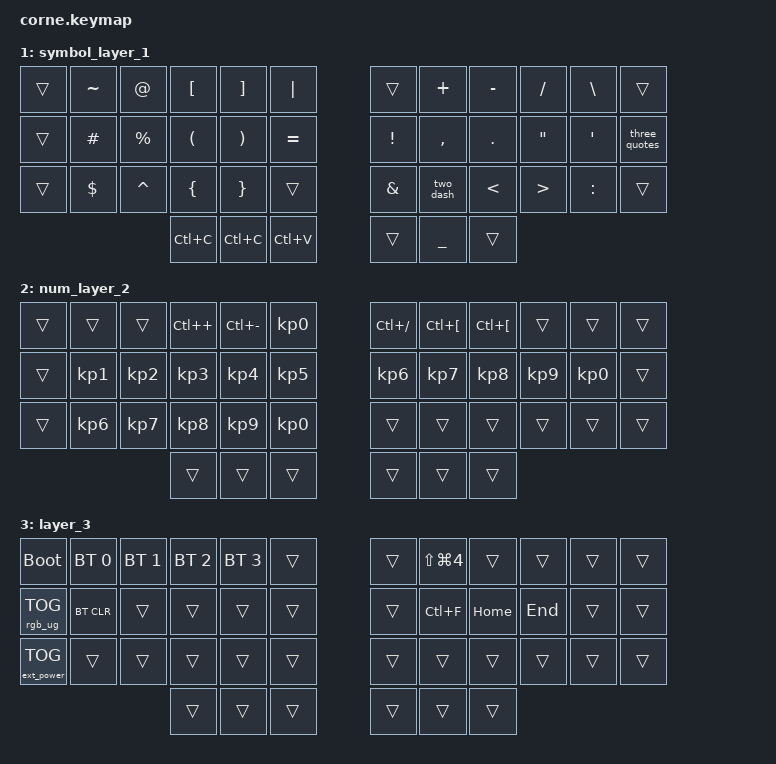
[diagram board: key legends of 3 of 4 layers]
/*
 * Copyright (c) 2020 The ZMK Contributors
 *
 * SPDX-License-Identifier: MIT
 */

#include <behaviors.dtsi>
#include <dt-bindings/zmk/bt.h>
#include <dt-bindings/zmk/keys.h>
#include <dt-bindings/zmk/rgb.h>
#include <dt-bindings/zmk/ext_power.h>
/ {
    behaviors {
        hm: homerow_mods {
            compatible = "zmk,behavior-hold-tap";
            label = "HOMEROW_MODS";
            #binding-cells = <2>;
            tapping-term-ms = <200>;
            quick_tap_ms = <0>;
            flavor = "tap-preferred";
            bindings = <&kp>, <&kp>;

            quick-tap-ms = <180>;
            global-quick-tap;
        };

        ltq: ltq {
            compatible = "zmk,behavior-hold-tap";
            label = "LTQ";
            bindings = <&mo>, <&kp>;
            #binding-cells = <2>;
            tapping-term-ms = <600>;
            global-quick-tap;
            quick-tap-ms = <400>;
        };

    };

    macros {
        three_quotes: three_quotes {
            compatible = "zmk,behavior-macro";
            #binding-cells = <0>;
            bindings = <&kp SQT &kp SQT &kp SQT>;
        };

       two_dash: two_dash {
            compatible = "zmk,behavior-macro";
            #binding-cells = <0>;
            bindings = <&kp MINUS &kp MINUS>;
        };

        mcr_lg_up: mcr_lg_up {
            compatible = "zmk,behavior-macro";
            #binding-cells = <0>;
            bindings = <&kp LG(UP)>;
        };

        mcr_lg_left: mcr_lg_left {
            compatible = "zmk,behavior-macro";
            #binding-cells = <0>;
            bindings = <&kp LG(LEFT)>;
        };

        mcr_lg_right: mcr_lg_right {
            compatible = "zmk,behavior-macro";
            #binding-cells = <0>;
            bindings = <&kp LG(RIGHT)>;
        };
    };

    combos {
        compatible = "zmk,combos";

        left_bkt {
            bindings = <&kp LEFT_BRACKET>;
            key-positions = <4 3>;
            timeout-ms = <50>;
        };

        right_bkt {
            bindings = <&kp RBKT>;
            key-positions = <7 8>;
            timeout-ms = <50>;
        };

        left_par {
            bindings = <&kp LEFT_PARENTHESIS>;
            key-positions = <15 16>;
            timeout-ms = <50>;
        };

        right_par {
            bindings = <&kp RIGHT_PARENTHESIS>;
            key-positions = <19 20>;
            timeout-ms = <50>;
        };

        left_brace {
            bindings = <&kp LEFT_BRACE>;
            key-positions = <27 28>;
            timeout-ms = <50>;
        };

        right_brace {
            bindings = <&kp RIGHT_BRACE>;
            key-positions = <32 31>;
            timeout-ms = <50>;
        };

        bac {
            bindings = <&kp BACKSLASH>;
            key-positions = <5 6>;
        };

        pipe {
            bindings = <&kp PIPE>;
            key-positions = <17 18>;
        };
    };

    keymap {
        compatible = "zmk,keymap";

        default_layer_0 {
            bindings = <
&kp LEFT_ARROW &mt RIGHT Q     &mt LG(UP) W    &mt LG(LEFT) F       &mt LG(RIGHT) R      &kp Y          &kp U             &kp I            &kp O            &kp LG(SPACE)           &kp UP_ARROW
&kp LG(ENTER)  &hm LEFT_GUI A  &hm LEFT_ALT S  &hm LCTRL D          &hm LEFT_SHIFT T     &kp J             &kp H          &hm RSHIFT N      &hm RCTRL E      &hm RIGHT_ALT L  &hm RGUI P              &kp DOWN_ARROW
&kp LC(Z)      &kp Z           &kp X           &kp C                &ltq 3 V             &kp B             &kp K          &ltq 2 M          &kp F4           &kp QUESTION     &hm SEMICOLON ASTRK     &kp ESC
                                               &kp LS(ENTER)        &sl 1                &mt LSHIFT ENTER  &kp BACKSPACE  &kp SPACE         &kp TAB
            >;
        };

        symbol_layer_1 {
            bindings = <
&trans      &kp TILDE  &kp AT_SIGN  &kp LBKT  &kp RBKT  &kp PIPE            &trans            &kp PLUS          &kp MINUS     &kp SLASH          &kp BSLH          &trans
&trans      &kp HASH   &kp PERCENT  &kp LPAR  &kp RPAR  &kp EQUAL           &kp EXCLAMATION   &kp COMMA         &kp PERIOD    &kp DOUBLE_QUOTES  &kp SINGLE_QUOTE  &three_quotes
&trans      &kp DOLLAR &kp CARET    &kp LBRC  &kp RBRC  &trans              &kp AMPERSAND     &two_dash         &kp LESS_THAN &kp GREATER_THAN   &kp COLON         &trans
                                    &kp LC(C) &kp LC(C) &kp LC(V)           &trans            &kp UNDERSCORE    &trans
            >;
        };

        num_layer_2 {
            bindings = <
&trans  &trans             &trans           &kp LC(PLUS)     &kp LC(MINUS)       &kp KP_NUMBER_0          &kp LC(SLASH)      &kp LC(LBKT)    &kp LC(LBKT)    &trans           &trans           &trans
&trans  &kp KP_NUMBER_1    &kp KP_NUMBER_2  &kp KP_NUMBER_3  &kp KP_NUMBER_4  &kp KP_NUMBER_5          &kp KP_NUMBER_6    &kp KP_NUMBER_7 &kp KP_NUMBER_8 &kp KP_NUMBER_9  &kp KP_NUMBER_0  &trans
&trans  &kp KP_NUMBER_6    &kp KP_NUMBER_7  &kp KP_NUMBER_8  &kp KP_NUMBER_9  &kp KP_NUMBER_0          &trans             &trans          &trans          &trans           &trans           &trans
                                            &trans           &trans           &trans                   &trans             &trans          &trans
            >;
        };

        layer_3 {
            bindings = <
&bootloader        &bt BT_SEL 0  &bt BT_SEL 1  &bt BT_SEL 2  &bt BT_SEL 3  &trans              &trans  &kp LS(LG(N4)) &trans    &trans  &trans  &trans
&rgb_ug RGB_TOG    &bt BT_CLR    &trans        &trans        &trans        &trans              &trans  &kp LC(F)      &kp HOME  &kp END &trans  &trans
&ext_power EP_TOG  &trans        &trans        &trans        &trans        &trans              &trans  &trans         &trans    &trans  &trans  &trans
                                               &trans        &trans        &trans              &trans  &trans         &trans
            >;
        };
        extra1 {
            status = "reserved";
        };
        extra2 {
            status = "reserved";
        };
        extra3 {
            status = "reserved";
        };
        extra4 {
            status = "reserved";
        };

    };
};
